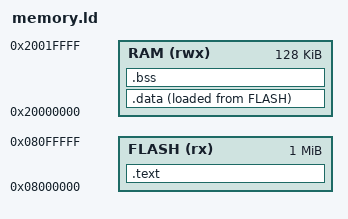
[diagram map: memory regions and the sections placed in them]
/* HardyRTOS Linker Script: STM32F407VG */
MEMORY
{
    FLASH (rx)  : ORIGIN = 0x08000000, LENGTH = 1024K
    RAM   (rwx) : ORIGIN = 0x20000000, LENGTH = 128K
}

SECTIONS
{
    .text : {
        KEEP(*(.isr_vector))
        *(.text*)
        *(.rodata*)
        . = ALIGN(4);
        _etext = .;
    } > FLASH

    _sidata = LOADADDR(.data);
    .data : {
        _sdata = .;
        *(.data*)
        . = ALIGN(4);
        _edata = .;
    } > RAM AT> FLASH

    .bss : {
        _sbss = .;
        *(.bss*)
        *(COMMON)
        . = ALIGN(4);
        _ebss = .;
    } > RAM

    _estack = ORIGIN(RAM) + LENGTH(RAM);
}
